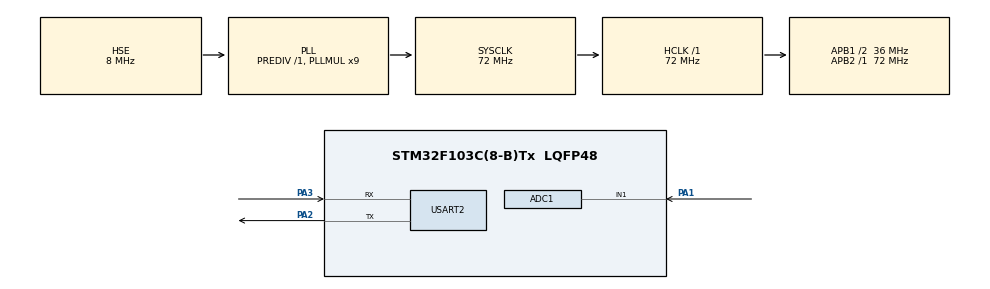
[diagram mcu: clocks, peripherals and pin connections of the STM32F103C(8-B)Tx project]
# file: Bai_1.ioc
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ADC1.Channel-0\#ChannelRegularConversion=ADC_CHANNEL_1
ADC1.NbrOfConversionFlag=1
ADC1.Rank-0\#ChannelRegularConversion=1
ADC1.SamplingTime-0\#ChannelRegularConversion=ADC_SAMPLETIME_1CYCLE_5
ADC1.master=1
FREERTOS.Tasks01=defaultTask,24,128,StartDefaultTask,Default,NULL,Dynamic,NULL,NULL;myTask02,8,128,StartTask02,Default,NULL,Dynamic,NULL,NULL
Mcu.Family=STM32F1
Mcu.Name=STM32F103C(8-B)Tx
Mcu.Package=LQFP48
NVIC.PriorityGroup=NVIC_PRIORITYGROUP_4
NVIC.USART2_IRQn=true\:5\:0\:false\:false\:true\:true\:true\:true
PA1.Signal=ADCx_IN1
PA13.Mode=Serial_Wire
PA13.Signal=SYS_JTMS-SWDIO
PA14.Mode=Serial_Wire
PA14.Signal=SYS_JTCK-SWCLK
PA2.Mode=Asynchronous
PA2.Signal=USART2_TX
PA3.Mode=Asynchronous
PA3.Signal=USART2_RX
PD0-OSC_IN.Mode=HSE-External-Oscillator
PD0-OSC_IN.Signal=RCC_OSC_IN
PD1-OSC_OUT.Mode=HSE-External-Oscillator
PD1-OSC_OUT.Signal=RCC_OSC_OUT
ProjectManager.HeapSize=0x200
ProjectManager.StackSize=0x400
ProjectManager.TargetToolchain=MDK-ARM V5.27
RCC.ADCPresc=RCC_ADCPCLK2_DIV6
RCC.AHBFreq_Value=72000000
RCC.APB1CLKDivider=RCC_HCLK_DIV2
RCC.APB1Freq_Value=36000000
RCC.APB1TimFreq_Value=72000000
RCC.APB2Freq_Value=72000000
RCC.APB2TimFreq_Value=72000000
RCC.HCLKFreq_Value=72000000
RCC.PLLMUL=RCC_PLL_MUL9
RCC.PLLSourceVirtual=RCC_PLLSOURCE_HSE
RCC.SYSCLKFreq_VALUE=72000000
RCC.SYSCLKSource=RCC_SYSCLKSOURCE_PLLCLK
RCC.USBFreq_Value=72000000
SH.ADCx_IN1.0=ADC1_IN1,IN1
USART2.VirtualMode=VM_ASYNC
VP_FREERTOS_VS_CMSIS_V2.Mode=CMSIS_V2
board=custom

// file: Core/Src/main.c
/* USER CODE BEGIN Header */
/**
  ******************************************************************************
  * @file           : main.c
  * @brief          : Main program body
  ******************************************************************************
  * @attention
  *
  * <h2><center>&copy; Copyright (c) 2022 STMicroelectronics.
  * All rights reserved.</center></h2>
  *
  * This software component is licensed by ST under Ultimate Liberty license
  * SLA0044, the "License"; You may not use this file except in compliance with
  * the License. You may obtain a copy of the License at:
  *                             www.st.com/SLA0044
  *
  ******************************************************************************
  */
/* USER CODE END Header */
#include "main.h"
#include "cmsis_os.h"

/* USER CODE BEGIN Includes */
#include "stdio.h"
/* USER CODE END Includes */

ADC_HandleTypeDef hadc1;

UART_HandleTypeDef huart2;

/* Definitions for defaultTask */
osThreadId_t defaultTaskHandle;
const osThreadAttr_t defaultTask_attributes = {
  .name = "defaultTask",
  .stack_size = 128 * 4,
  .priority = (osPriority_t) osPriorityNormal,
};
/* Definitions for myTask02 */
osThreadId_t myTask02Handle;
const osThreadAttr_t myTask02_attributes = {
  .name = "myTask02",
  .stack_size = 128 * 4,
  .priority = (osPriority_t) osPriorityLow,
};

void SystemClock_Config(void);
static void MX_GPIO_Init(void);
static void MX_ADC1_Init(void);
static void MX_USART2_UART_Init(void);
void StartDefaultTask(void *argument);
void StartTask02(void *argument);

/* USER CODE BEGIN PFP */
/*int __io_putchar(int ch)
{
	HAL_UART_Transmit(&huart2,(uint8_t *)&ch,1,0x10);
	return ch;
}*/
/* USER CODE END PFP */

/* USER CODE BEGIN 0 */
float lux=0.0;
/* USER CODE END 0 */

int main(void)
{

  /* MCU Configuration--------------------------------------------------------*/

  /* Reset of all peripherals, Initializes the Flash interface and the Systick. */
  HAL_Init();

  /* Configure the system clock */
  SystemClock_Config();

  /* Initialize all configured peripherals */
  MX_GPIO_Init();
  MX_ADC1_Init();
  MX_USART2_UART_Init();

  /* Init scheduler */
  osKernelInitialize();

  /* Create the thread(s) */
  /* creation of defaultTask */
  defaultTaskHandle = osThreadNew(StartDefaultTask, NULL, &defaultTask_attributes);

  /* creation of myTask02 */
  myTask02Handle = osThreadNew(StartTask02, NULL, &myTask02_attributes);

  /* Start scheduler */
  osKernelStart();

  /* We should never get here as control is now taken by the scheduler */
  /* Infinite loop */
  while (1)
  {

  }
}

void SystemClock_Config(void)
{
  RCC_OscInitTypeDef RCC_OscInitStruct = {0};
  RCC_ClkInitTypeDef RCC_ClkInitStruct = {0};
  RCC_PeriphCLKInitTypeDef PeriphClkInit = {0};

  /** Initializes the RCC Oscillators according to the specified parameters
  * in the RCC_OscInitTypeDef structure.
  */
  RCC_OscInitStruct.OscillatorType = RCC_OSCILLATORTYPE_HSE;
  RCC_OscInitStruct.HSEState = RCC_HSE_ON;
  RCC_OscInitStruct.HSEPredivValue = RCC_HSE_PREDIV_DIV1;
  RCC_OscInitStruct.HSIState = RCC_HSI_ON;
  RCC_OscInitStruct.PLL.PLLState = RCC_PLL_ON;
  RCC_OscInitStruct.PLL.PLLSource = RCC_PLLSOURCE_HSE;
  RCC_OscInitStruct.PLL.PLLMUL = RCC_PLL_MUL9;
  if (HAL_RCC_OscConfig(&RCC_OscInitStruct) != HAL_OK)
  {
    Error_Handler();
  }
  /** Initializes the CPU, AHB and APB buses clocks
  */
  RCC_ClkInitStruct.ClockType = RCC_CLOCKTYPE_HCLK|RCC_CLOCKTYPE_SYSCLK
                              |RCC_CLOCKTYPE_PCLK1|RCC_CLOCKTYPE_PCLK2;
  RCC_ClkInitStruct.SYSCLKSource = RCC_SYSCLKSOURCE_PLLCLK;
  RCC_ClkInitStruct.AHBCLKDivider = RCC_SYSCLK_DIV1;
  RCC_ClkInitStruct.APB1CLKDivider = RCC_HCLK_DIV2;
  RCC_ClkInitStruct.APB2CLKDivider = RCC_HCLK_DIV1;

  if (HAL_RCC_ClockConfig(&RCC_ClkInitStruct, FLASH_LATENCY_2) != HAL_OK)
  {
    Error_Handler();
  }
  PeriphClkInit.PeriphClockSelection = RCC_PERIPHCLK_ADC;
  PeriphClkInit.AdcClockSelection = RCC_ADCPCLK2_DIV6;
  if (HAL_RCCEx_PeriphCLKConfig(&PeriphClkInit) != HAL_OK)
  {
    Error_Handler();
  }
}

static void MX_ADC1_Init(void)
{

  ADC_ChannelConfTypeDef sConfig = {0};

  /** Common config
  */
  hadc1.Instance = ADC1;
  hadc1.Init.ScanConvMode = ADC_SCAN_DISABLE;
  hadc1.Init.ContinuousConvMode = DISABLE;
  hadc1.Init.DiscontinuousConvMode = DISABLE;
  hadc1.Init.ExternalTrigConv = ADC_SOFTWARE_START;
  hadc1.Init.DataAlign = ADC_DATAALIGN_RIGHT;
  hadc1.Init.NbrOfConversion = 1;
  if (HAL_ADC_Init(&hadc1) != HAL_OK)
  {
    Error_Handler();
  }
  /** Configure Regular Channel
  */
  sConfig.Channel = ADC_CHANNEL_1;
  sConfig.Rank = ADC_REGULAR_RANK_1;
  sConfig.SamplingTime = ADC_SAMPLETIME_1CYCLE_5;
  if (HAL_ADC_ConfigChannel(&hadc1, &sConfig) != HAL_OK)
  {
    Error_Handler();
  }

}

static void MX_USART2_UART_Init(void)
{

  huart2.Instance = USART2;
  huart2.Init.BaudRate = 9600;
  huart2.Init.WordLength = UART_WORDLENGTH_8B;
  huart2.Init.StopBits = UART_STOPBITS_1;
  huart2.Init.Parity = UART_PARITY_NONE;
  huart2.Init.Mode = UART_MODE_TX_RX;
  huart2.Init.HwFlowCtl = UART_HWCONTROL_NONE;
  huart2.Init.OverSampling = UART_OVERSAMPLING_16;
  if (HAL_UART_Init(&huart2) != HAL_OK)
  {
    Error_Handler();
  }

}

static void MX_GPIO_Init(void)
{

  /* GPIO Ports Clock Enable */
  __HAL_RCC_GPIOD_CLK_ENABLE();
  __HAL_RCC_GPIOA_CLK_ENABLE();

}

void StartDefaultTask(void *argument)
{
  /* USER CODE BEGIN 5 */
  /* Infinite loop */
  for(;;)
  {
		int i=0;
		uint32_t tong=0;
		while(i<10)
		{
		HAL_ADC_Start(&hadc1);
		tong+=HAL_ADC_GetValue(&hadc1);
		HAL_ADC_Stop(&hadc1);
			i++;
			osDelay(50);
		}
		lux=250/((float)(tong)/10*3.3/4095);// cong thuc tinh lux
    osDelay(1000);
  }
  /* USER CODE END 5 */
}

void StartTask02(void *argument)
{
  /* USER CODE BEGIN StartTask02 */
  /* Infinite loop */
  for(;;)
  {
		char str[30];
		for(int i=0;i<30;i++)
		{
			str[i]=0;
		}
		sprintf(str,"anh sang:%f lux\n",lux);
		HAL_UART_Transmit(&huart2,(uint8_t *)str,sizeof(str)-1,100);
		//printf(" nhiet do: %f\n",nd);
    osDelay(3000);
  }
  /* USER CODE END StartTask02 */
}

void Error_Handler(void)
{
  __disable_irq();
  while (1)
  {
  }
}

/************************ (C) COPYRIGHT STMicroelectronics *****END OF FILE****/
